# STM32H7RSxx register map
File version: 0.2
CPU: CM7 r0p1, little endian, MPU, FPU, 4 interrupt priority bits
Registers are 32-bit, read-write, reset 0x0 unless marked. A register's access mark holds for its fields unless they carry their own. Offsets are from the block's base; [hi:lo] are bit positions; {n}, {i} and the like mark numbered series; 'fields as' and 'values as' point back to an identical list.

## EXTI — Extended interrupt and event controller
Base 0x58000000
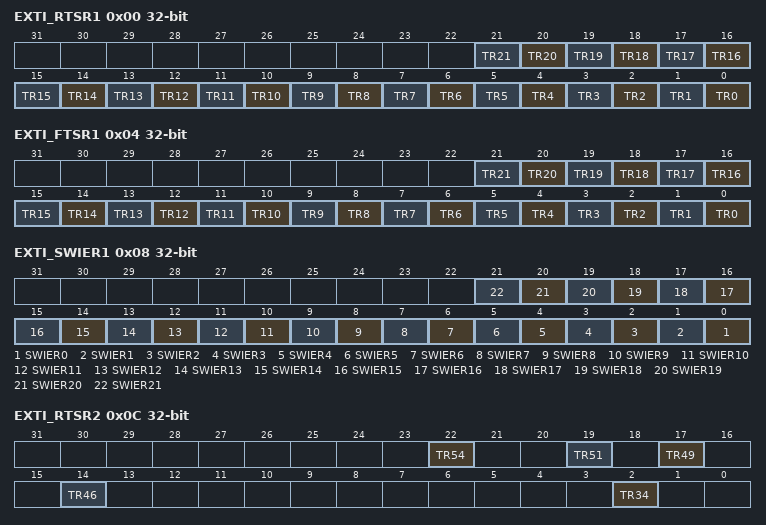
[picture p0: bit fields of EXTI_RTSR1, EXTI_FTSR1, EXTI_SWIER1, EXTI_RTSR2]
0x00 EXTI_RTSR1 — EXTI rising trigger selection register
  [all] fields
    0=Rising trigger disabled (for event and interrupt) for input line; 1=Rising trigger enabled (for event and interrupt) for input line
  [n] TR{n} (n=0..21) — Rising trigger event configuration bit of configurable event input x.
0x04 EXTI_FTSR1 — EXTI falling trigger selection register
  [all] fields
    0=Falling trigger disabled (for event and interrupt) for input line; 1=Falling trigger enabled (for event and interrupt) for input line
  [n] TR{n} (n=0..21) — Falling trigger event configuration bit of configurable event input x.
0x08 EXTI_SWIER1 — EXTI software interrupt event register
  [all] fields
    0=Writing 0 has no effect; 1=Writing a 1 to this bit triggers an event on line x. This bit is auto cleared by HW.
  [n] SWIER{n} (n=0..21) — Software interrupt on line x This bitfield alway returns 0 when read.
0x0C EXTI_RTSR2 — EXTI rising trigger selection register
  [all] fields
    values as the fields of EXTI_RTSR1
  [22] TR54 — Rising trigger event configuration bit of configurable event input x+32.
  [19] TR51 — Rising trigger event configuration bit of configurable event input x+32.<sup>(1)</sup>
  [17] TR49 — Rising trigger event configuration bit of configurable event input x+32.<sup>(1)</sup>
  [14] TR46 — Rising trigger event configuration bit of configurable event input x+32.<sup>(1)</sup>
  [2] TR34 — Rising trigger event configuration bit of configurable event input x+32.<sup>(1)</sup>
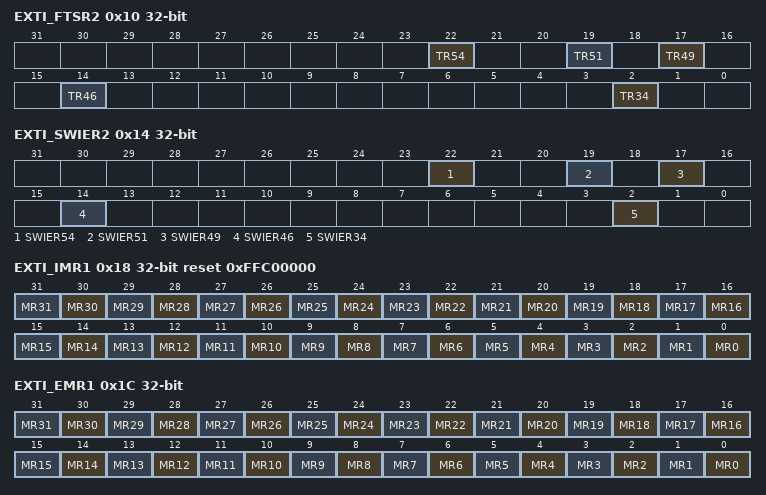
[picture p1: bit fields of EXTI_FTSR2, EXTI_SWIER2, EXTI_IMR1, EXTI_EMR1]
0x10 EXTI_FTSR2 — EXTI falling trigger selection register
  [all] fields
    values as the fields of EXTI_FTSR1
  [22] TR54 — Falling trigger event configuration bit of configurable event input x+32.
  [19] TR51 — Falling trigger event configuration bit of configurable event input x+32.<sup>(1)</sup>
  [17] TR49 — Falling trigger event configuration bit of configurable event input x+32.<sup>(1)</sup>
  [14] TR46 — Falling trigger event configuration bit of configurable event input x+32.<sup>(1)</sup>
  [2] TR34 — Falling trigger event configuration bit of configurable event input x+32.<sup>(1)</sup>
0x14 EXTI_SWIER2 — EXTI software interrupt event register
  [all] fields
    values as the fields of EXTI_SWIER1
  [22] SWIER54 — Software interrupt on line x+32 Always returns 0 when read.
  [19] SWIER51 — Software interrupt on line x+32 Always returns 0 when read.
  [17] SWIER49 — Software interrupt on line x+32 Always returns 0 when read.
  [14] SWIER46 — Software interrupt on line x+32 Always returns 0 when read.
  [2] SWIER34 — Software interrupt on line x+32 Always returns 0 when read.
0x18 EXTI_IMR1 reset 0xFFC00000 — EXTI interrupt mask register
  [all] fields
    0=Interrupt request from line x is masked; 1=Interrupt request from line x is unmasked
  [n] MR{n} (n=22..31) — CPU interrupt mask on direct event input x
  [n] MR{n} (n=0..21) — CPU interrupt mask on configurable event input x
0x1C EXTI_EMR1 — EXTI event mask register
  [all] fields
    0=Event request from line x is masked; 1=Event request from line x is unmasked
  [n] MR{n} (n=0..31) — CPU event mask on event input x
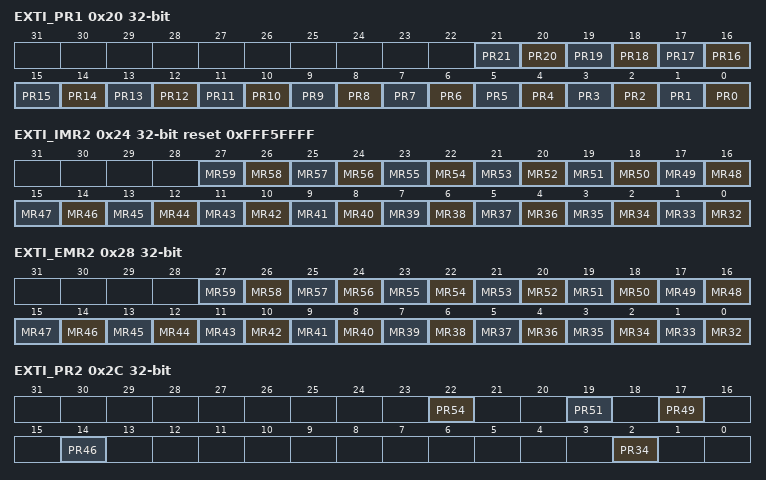
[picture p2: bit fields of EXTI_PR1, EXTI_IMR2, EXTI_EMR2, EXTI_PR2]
0x20 EXTI_PR1 reset not defined — EXTI pending register
  [all] fields
    0=No trigger request occurred; 1=selected trigger request occurred
  [n] PR{n} (n=0..21) — Configurable event inputs x Pending bit This bit is set when the selected edge event arrives on the external interrupt line. This bit is cleared by writing a 1 into the bit or by changing the sensitivity of the edge detector.
0x24 EXTI_IMR2 reset 0xFFF5FFFF — EXTI interrupt mask register
  [all] fields
    values as the fields of EXTI_IMR1
  [n-32] MR{n} (n=32..59) — CPU interrupt mask on direct event input i
0x28 EXTI_EMR2 — EXTI event mask register
  [n-32] MR{n} (n=32..59) — CPU event mask on event input i
    0=Event request from line {n} is masked; 1=Event request from line {n} is unmasked
0x2C EXTI_PR2 reset not defined — EXTI pending register
  [all] fields
    values as the fields of EXTI_PR1
  [22] PR54 — Configurable event inputs x+32 Pending bit This bit is set when the selected edge event arrives on the external interrupt line. This bit is cleared by writing a 1 into the bit or by changing the sensitivity of the edge detector.
  [19] PR51 — Configurable event inputs x+32 Pending bit This bit is set when the selected edge event arrives on the external interrupt line. This bit is cleared by writing a 1 into the bit or by changing the sensitivity of the edge detector.
  [17] PR49 — Configurable event inputs x+32 Pending bit This bit is set when the selected edge event arrives on the external interrupt line. This bit is cleared by writing a 1 into the bit or by changing the sensitivity of the edge detector.
  [14] PR46 — Configurable event inputs x+32 Pending bit This bit is set when the selected edge event arrives on the external interrupt line. This bit is cleared by writing a 1 into the bit or by changing the sensitivity of the edge detector.
  [2] PR34 — Configurable event inputs x+32 Pending bit This bit is set when the selected edge event arrives on the external interrupt line. This bit is cleared by writing a 1 into the bit or by changing the sensitivity of the edge detector.
0x30 EXTI_IMR3 reset 0xF8BFFFF — EXTI interrupt mask register
  [13] MR77 — CPU interrupt mask on direct event input x+64
    values as the fields of EXTI_IMR1
0x34 EXTI_EMR3 — EXTI event mask register
  [13] MR77 — CPU event mask on event input x+64
    values as the fields of EXTI_EMR1
